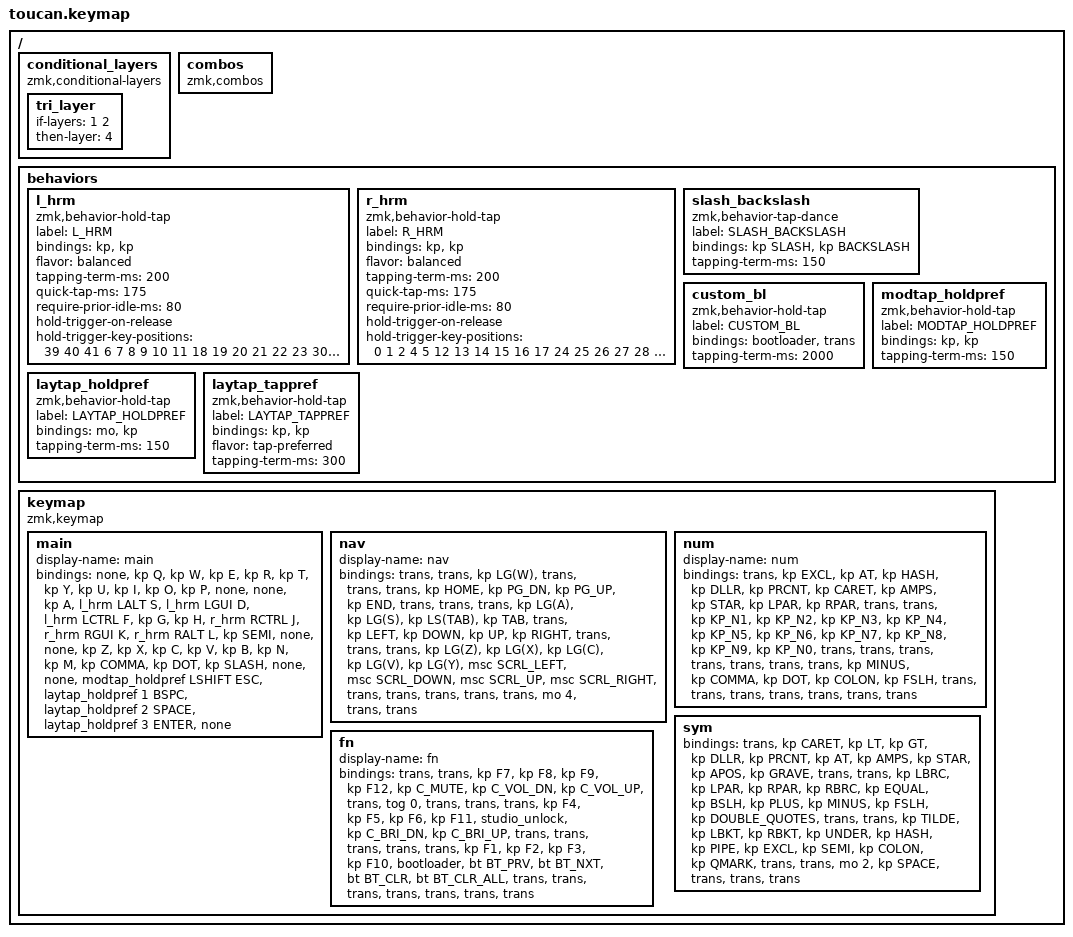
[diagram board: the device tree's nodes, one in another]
#include <behaviors.dtsi>
#include <dt-bindings/zmk/bt.h>
#include <dt-bindings/zmk/keys.h>
#include <dt-bindings/zmk/pointing.h>

/ {
    conditional_layers {
        compatible = "zmk,conditional-layers";

        tri_layer {
            if-layers = <1 2>;
            then-layer = <4>;
        };
    };

    combos { compatible = "zmk,combos"; };

    behaviors {
        l_hrm: l_hrm {
            compatible = "zmk,behavior-hold-tap";
            label = "L_HRM";
            bindings = <&kp>, <&kp>;

            #binding-cells = <2>;
            flavor = "balanced";
            tapping-term-ms = <200>;
            quick-tap-ms = <175>;
            require-prior-idle-ms = <80>;
            hold-trigger-on-release;
            hold-trigger-key-positions = <39 40 41 6 7 8 9 10 11 18 19 20 21 22 23 30 31 32 33 34 35>;
        };

        r_hrm: r_hrm {
            compatible = "zmk,behavior-hold-tap";
            label = "R_HRM";
            bindings = <&kp>, <&kp>;

            #binding-cells = <2>;
            flavor = "balanced";
            tapping-term-ms = <200>;
            quick-tap-ms = <175>;
            require-prior-idle-ms = <80>;
            hold-trigger-on-release;
            hold-trigger-key-positions = <0 1 2 4 5 12 13 14 15 16 17 24 25 26 27 28 29 36 37 38 3>;
        };

        slash_backslash: slash_backslash {
            compatible = "zmk,behavior-tap-dance";
            label = "SLASH_BACKSLASH";
            #binding-cells = <0>;
            bindings = <&kp SLASH>, <&kp BACKSLASH>;

            tapping-term-ms = <150>;
        };

        custom_bl: custom_bl {
            compatible = "zmk,behavior-hold-tap";
            label = "CUSTOM_BL";
            bindings = <&bootloader>, <&trans>;

            #binding-cells = <2>;
            tapping-term-ms = <2000>;
        };

        modtap_holdpref: modtap_holdpref {
            compatible = "zmk,behavior-hold-tap";
            label = "MODTAP_HOLDPREF";
            bindings = <&kp>, <&kp>;

            #binding-cells = <2>;
            tapping-term-ms = <150>;
        };

        laytap_holdpref: laytap_holdpref {
            compatible = "zmk,behavior-hold-tap";
            label = "LAYTAP_HOLDPREF";
            bindings = <&mo>, <&kp>;

            #binding-cells = <2>;
            tapping-term-ms = <150>;
        };

        laytap_tappref: laytap_tappref {
            compatible = "zmk,behavior-hold-tap";
            label = "LAYTAP_TAPPREF";
            bindings = <&kp>, <&kp>;

            #binding-cells = <2>;
            flavor = "tap-preferred";
            tapping-term-ms = <300>;
        };
    };

    keymap {
        compatible = "zmk,keymap";

        main {
            display-name = "main";
            bindings = <
&none  &kp Q  &kp W  &kp E  &kp R  &kp T  &kp Y  &kp U  &kp I  &kp O  &kp P  &none  &none  &kp A  &l_hrm LALT S  &l_hrm LGUI D  &l_hrm LCTRL F  &kp G  &kp H  &r_hrm RCTRL J  &r_hrm RGUI K  &r_hrm RALT L  &kp SEMI  &none  &none  &kp Z  &kp X  &kp C  &kp V  &kp B  &kp N  &kp M  &kp COMMA  &kp DOT  &kp SLASH  &none  &none  &modtap_holdpref LSHIFT ESC  &laytap_holdpref 1 BSPC  &laytap_holdpref 2 SPACE  &laytap_holdpref 3 ENTER  &none
            >;
        };

        nav {
            display-name = "nav";
            bindings = <
&trans  &trans  &kp LG(W)  &trans  &trans  &trans  &kp HOME  &kp PG_DN  &kp PG_UP  &kp END  &trans  &trans  &trans  &kp LG(A)  &kp LG(S)  &kp LS(TAB)  &kp TAB  &trans  &kp LEFT  &kp DOWN  &kp UP  &kp RIGHT  &trans  &trans  &trans  &kp LG(Z)  &kp LG(X)  &kp LG(C)  &kp LG(V)  &kp LG(Y)  &msc SCRL_LEFT  &msc SCRL_DOWN  &msc SCRL_UP  &msc SCRL_RIGHT  &trans  &trans  &trans  &trans  &trans  &mo 4  &trans  &trans
            >;
        };

        num {
            display-name = "num";
            bindings = <
&trans  &kp EXCL  &kp AT  &kp HASH  &kp DLLR  &kp PRCNT  &kp CARET  &kp AMPS  &kp STAR  &kp LPAR  &kp RPAR  &trans  &trans  &kp KP_N1  &kp KP_N2  &kp KP_N3  &kp KP_N4  &kp KP_N5  &kp KP_N6  &kp KP_N7  &kp KP_N8  &kp KP_N9  &kp KP_N0  &trans  &trans  &trans  &trans  &trans  &trans  &trans  &kp MINUS  &kp COMMA  &kp DOT  &kp COLON  &kp FSLH  &trans  &trans  &trans  &trans  &trans  &trans  &trans
            >;
        };

        sym {
            bindings = <
&trans  &kp CARET  &kp LT  &kp GT  &kp DLLR  &kp PRCNT  &kp AT  &kp AMPS  &kp STAR  &kp APOS  &kp GRAVE  &trans  &trans  &kp LBRC  &kp LPAR  &kp RPAR  &kp RBRC  &kp EQUAL  &kp BSLH  &kp PLUS  &kp MINUS  &kp FSLH  &kp DOUBLE_QUOTES  &trans  &trans  &kp TILDE  &kp LBKT  &kp RBKT  &kp UNDER  &kp HASH  &kp PIPE  &kp EXCL  &kp SEMI  &kp COLON  &kp QMARK  &trans  &trans  &mo 2  &kp SPACE  &trans  &trans  &trans
            >;
        };

        fn {
            display-name = "fn";
            bindings = <
&trans  &trans  &kp F7  &kp F8  &kp F9  &kp F12  &kp C_MUTE  &kp C_VOL_DN  &kp C_VOL_UP  &trans  &tog 0  &trans  &trans  &trans  &kp F4  &kp F5  &kp F6  &kp F11  &studio_unlock  &kp C_BRI_DN  &kp C_BRI_UP  &trans  &trans  &trans  &trans  &trans  &kp F1  &kp F2  &kp F3  &kp F10  &bootloader  &bt BT_PRV  &bt BT_NXT  &bt BT_CLR  &bt BT_CLR_ALL  &trans  &trans  &trans  &trans  &trans  &trans  &trans
            >;
        };
    };
};
